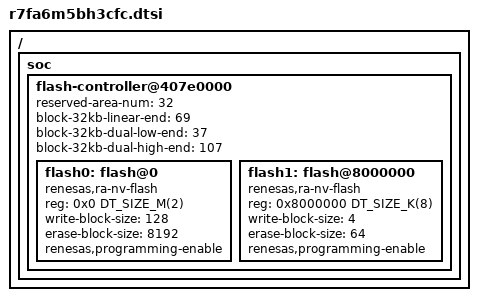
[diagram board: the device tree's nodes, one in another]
/*
 * Copyright (c) 2024 Renesas Electronics Corporation
 *
 * SPDX-License-Identifier: Apache-2.0
 */

#include <arm/renesas/ra/ra6/r7fa6m5xh.dtsi>

/ {
	soc {
		flash-controller@407e0000 {
			reserved-area-num = <32>;
			block-32kb-linear-end = <69>;
			block-32kb-dual-low-end = <37>;
			block-32kb-dual-high-end = <107>;
			flash0: flash@0 {
				compatible = "renesas,ra-nv-flash";
				reg = <0x0 DT_SIZE_M(2)>;
				write-block-size = <128>;
				erase-block-size = <8192>;
				renesas,programming-enable;
			};

			flash1: flash@8000000 {
				compatible = "renesas,ra-nv-flash";
				reg = <0x8000000 DT_SIZE_K(8)>;
				write-block-size = <4>;
				erase-block-size = <64>;
				renesas,programming-enable;
			};
		};
	};
};
